# XMC4700 register map
Vendor: Infineon; File version: 1.3.0 (Reference Manual v1.3)
CPU: CM4 r2p0, little endian, MPU, FPU, 6 interrupt priority bits
Registers are 32-bit, read-write, reset 0x0 unless marked. A register's access mark holds for its fields unless they carry their own. Offsets are from the block's base; [hi:lo] are bit positions; {n}, {i} and the like mark numbered series; 'fields as' and 'values as' point back to an identical list.

## PORT0
Base 0x48028000
Same registers: PORT{n} {0x48028000+0x100*n} (n=1..9), PORT14 0x48028E00, PORT15 0x48028F00
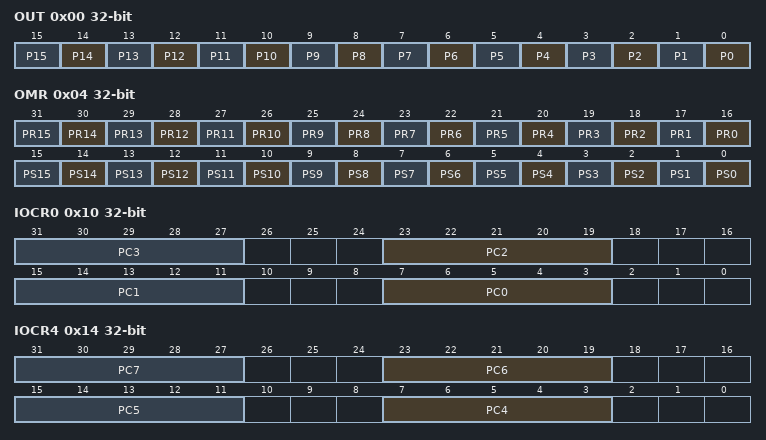
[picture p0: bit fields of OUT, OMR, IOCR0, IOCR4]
0x00 OUT — Port 0 Output Register
  [all] fields
    0=The output level of Pn.x is 0; 1=The output level of Pn.x is 1
  [n] P{n} (n=0..15) — Port n Output Bit {n}
0x04 OMR wo — Port 0 Output Modification Register
  [n+16] PR{n} (n=0..15) — Port n Reset Bit {n}
  [n] PS{n} (n=0..15) — Port n Set Bit {n}
0x10 IOCR0 — Port 0 Input/Output Control Register 0
  [all] fields
    0=Input - No internal pull device active; 1=input_pulldown (Input - Internal pull-down device active); 2=input_pullup (Input - Internal pull-up device active); 3=input_sampled (Input - No internal pull device, Pn_OUTx = input value); 4=Input inverted - No internal pull device active; 5=input_inv_pulldown (Input inverted - Internal pull-down device active); 6=input_inv_pullup (Input inverted - Internal pull-up device active); 7=input_inv_sampled (Input inverted - No internal pull device, Pn_OUTx = input value); 16=Output Push-Pull - General-purpose output; {v}=output_af{v-16} (Output Push-Pull - Alternate output function {v-16}) (v=17..20); 24=output_od (Output Open Drain - General-purpose output); {v}=output_od_af{v-24} (Output Open Drain - Alternate output function {v-24}) (v=25..28)
  [8n+7:8n+3] PC{n} (n=0..3) — Port Control for Port n Pin 0 to 3
0x14 IOCR4 — Port 0 Input/Output Control Register 4
  [all] fields
    values as the fields of IOCR0
  [8n-25:8n-29] PC{n} (n=4..7) — Port Control for Port n Pin 4 to 7
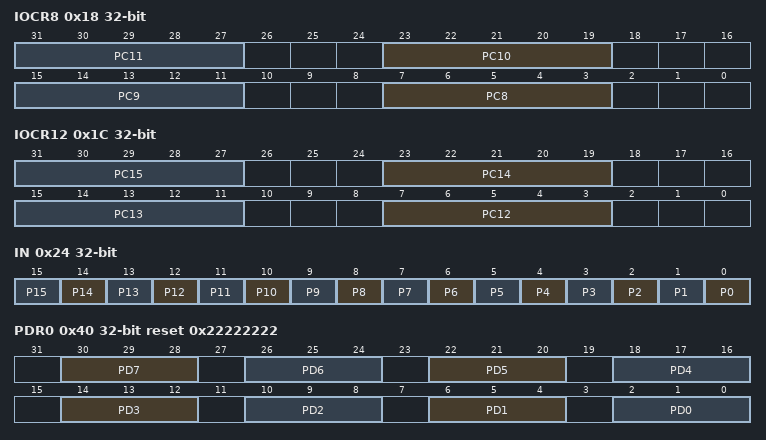
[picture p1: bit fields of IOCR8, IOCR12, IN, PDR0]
0x18 IOCR8 — Port 0 Input/Output Control Register 8
  [all] fields
    values as the fields of IOCR0
  [8n-57:8n-61] PC{n} (n=8..11) — Port Control for Port n Pin 8 to 11
0x1C IOCR12 — Port 0 Input/Output Control Register 12
  [all] fields
    values as the fields of IOCR0
  [8n-89:8n-93] PC{n} (n=12..15) — Port Control for Port n Pin 12 to 15
0x24 IN ro (reset mask 0xFFFF0000) — Port 0 Input Register
  [all] fields
    0=The input level of Pn.x is 0; 1=The input level of Pn.x is 1
  [n] P{n} (n=0..15) — Port n Input Bit {n}
0x40 PDR0 reset 0x22222222 — Port 0 Pad Driver Mode 0 Register
  [30:28] PD7 — Pad Driver Mode for Pn.7
    0=sd_she (A2 strong driver, sharp edge); 1=sd_mee (A2 strong driver, medium edge); 2=sd_soe (A2 strong driver, soft edge); 4=md (A2 medium driver); 7=wd (A2 weak driver)
  [26:24] PD6 — Pad Driver Mode for Pn.6
    values as PD7
  [22:20] PD5 — Pad Driver Mode for Pn.5
    values as PD7
  [18:16] PD4 — Pad Driver Mode for Pn.4
    values as PD7
  [14:12] PD3 — Pad Driver Mode for Pn.3
    values as PD7
  [10:8] PD2 — Pad Driver Mode for Pn.2
    values as PD7
  [6:4] PD1 — Pad Driver Mode for Pn.1
    2=sd_soe (A1+ strong driver, soft edge); 3=sd_sle (A1+ strong driver, slow edge); 4=md (A1+ medium driver); 7=wd (A1+ weak driver); 0=sd_soe_alt (A1+ strong driver, soft edge (alternate value)); 1=sd_sle_alt (A1+ strong driver, slow edge (alternate value)); 6=md_alt (A1+ medium driver (alternate value)); 5=wd_alt (A1+ weak driver (alternate value))
  [2:0] PD0 — Pad Driver Mode for Pn.0
    values as PD1
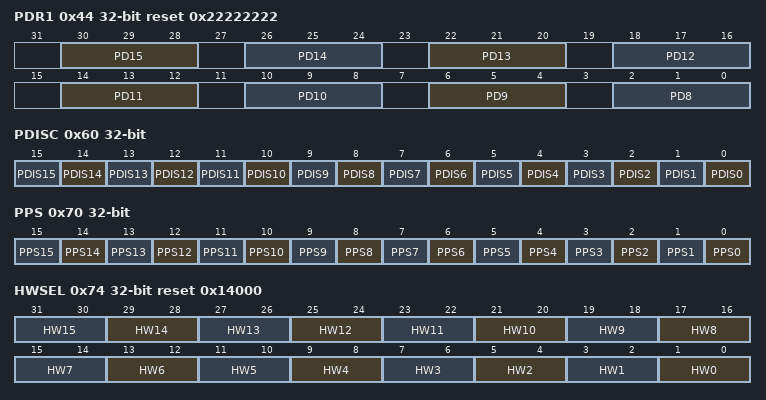
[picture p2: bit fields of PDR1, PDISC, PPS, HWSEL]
0x44 PDR1 reset 0x22222222 — Port 0 Pad Driver Mode 1 Register
  [30:28] PD15 — Pad Driver Mode for Pn.15
    values as PDR0.PD1
  [26:24] PD14 — Pad Driver Mode for Pn.14
    values as PDR0.PD1
  [22:20] PD13 — Pad Driver Mode for Pn.13
    values as PDR0.PD1
  [18:16] PD12 — Pad Driver Mode for Pn.12
    values as PDR0.PD1
  [14:12] PD11 — Pad Driver Mode for Pn.11
    values as PDR0.PD1
  [10:8] PD10 — Pad Driver Mode for Pn.10
    values as PDR0.PD1
  [6:4] PD9 — Pad Driver Mode for Pn.9
    values as PDR0.PD7
  [2:0] PD8 — Pad Driver Mode for Pn.8
    values as PDR0.PD7
0x60 PDISC ro (reset mask 0xFFFF0000) — Port 0 Pin Function Decision Control Register
  [all] fields
    0=Pad Pn.x is enabled; 1=Pad Pn.x is disabled
  [n] PDIS{n} (n=0..15) — Pad Disable for Port n Pin {n}
0x70 PPS — Port 0 Pin Power Save Register
  [all] fields
    0=Pin Power Save of Pn.x is disabled; 1=Pin Power Save of Pn.x is enabled
  [n] PPS{n} (n=0..15) — Port n Pin Power Save Bit {n}
0x74 HWSEL reset 0x14000 — Port 0 Pin Hardware Select Register
  [all] fields
    0=Software control only; 1=HW0 control path can override the software configuration; 2=HW1 control path can override the software configuration
  [2n+1:2n] HW{n} (n=0..15) — Port n Pin Hardware Select Bit {n}
